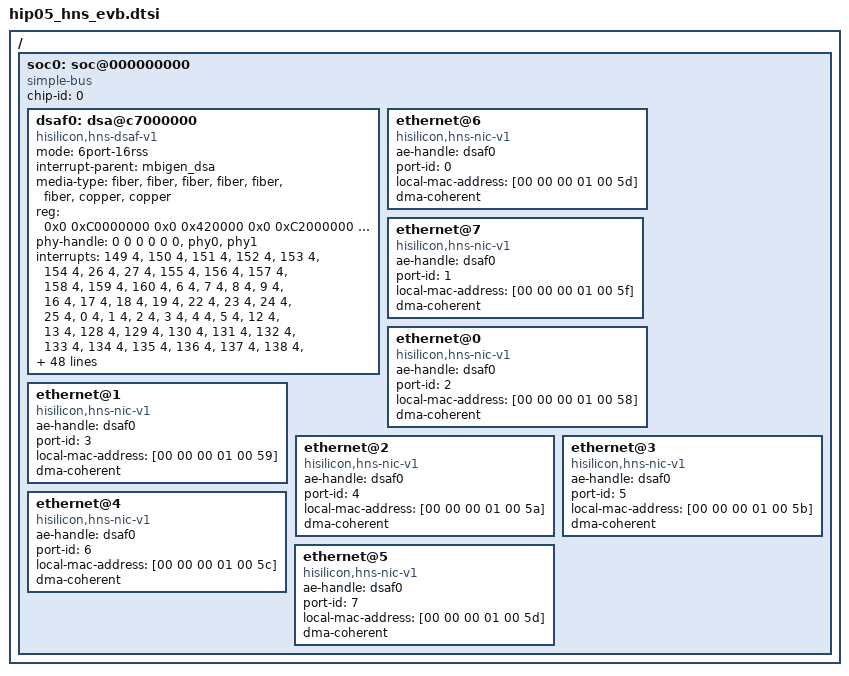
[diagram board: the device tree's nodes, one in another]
/ {
	soc0: soc@000000000 {
		#address-cells = <2>;
		#size-cells = <2>;
		device_type = "soc";
		compatible = "simple-bus";
		ranges = <0x0 0x0 0x0 0x0 0x1 0x0>;
		chip-id = <0>;

		dsaf0: dsa@c7000000 {
			compatible = "hisilicon,hns-dsaf-v1";
			mode = "6port-16rss";
			interrupt-parent = <&mbigen_dsa>;
			media-type = "fiber", "fiber", "fiber", "fiber",
				"fiber", "fiber", "copper", "copper";
			reg = <0x0 0xC0000000 0x0 0x420000
				0x0 0xC2000000 0x0 0x300000
				0x0 0xc5000000 0x0 0x890000
				0x0 0xc7000000 0x0 0x60000
				>;

			phy-handle = <0 0 0 0 0 0 &phy0 &phy1>;
			interrupts =
					/* [14] ge fifo err 8 / xge 6**/
					<149 4>,<150 4>,
					<151 4>,<152 4>,
					<153 4>,<154 4>,
					<26 4>,<27 4>,
					<155 4>,<156 4>,
					<157 4>,<158 4>,
					<159 4>,<160 4>,
					/* [12] rcb com 4*3**/
					<6 4>,<7 4>,
					<8 4>,<9 4>,
					<16 4>,<17 4>,
					<18 4>,<19 4>,
					<22 4>,<23 4>,
					<24 4>,<25 4>,
					/* [8] ppe tnl 0-7***/
					<0 4>,<1 4>,
					<2 4>,<3 4>,
					<4 4>,<5 4>,
					<12 4>,<13 4>,
					/* [21] dsaf event int 3+18**/
					<128 4>,<129 4>,
					<130 4>,<131 4>,
					<132 4>,<133 4>,
					<134 4>,<135 4>,
					<136 4>,<137 4>,
					<138 4>,<139 4>,
					<140 4>,<141 4>,
					<142 4>,<143 4>,
					<144 4>,<145 4>,
					<146 4>,<147 4>,
					<148 4>,
					/* [4] debug rcb 2*2*/
					<14 1>,<15 1>,
					<20 1>,<21 1>,
					/* [256] sevice rcb 2*128*/
					<384 1>,<385 1>,
					<386 1>,<387 1>,
					<388 1>,<389 1>,
					<390 1>,<391 1>,
					<392 1>,<393 1>,
					<394 1>,<395 1>,
					<396 1>,<397 1>,
					<398 1>,<399 1>,
					<400 1>,<401 1>,
					<402 1>,<403 1>,
					<404 1>,<405 1>,
					<406 1>,<407 1>,
					<408 1>,<409 1>,
					<410 1>,<411 1>,
					<412 1>,<413 1>,
					<414 1>,<415 1>,
					<416 1>,<417 1>,
					<418 1>,<419 1>,
					<420 1>,<421 1>,
					<422 1>,<423 1>,
					<424 1>,<425 1>,
					<426 1>,<427 1>,
					<428 1>,<429 1>,
					<430 1>,<431 1>,
					<432 1>,<433 1>,
					<434 1>,<435 1>,
					<436 1>,<437 1>,
					<438 1>,<439 1>,
					<440 1>,<441 1>,
					<442 1>,<443 1>,
					<444 1>,<445 1>,
					<446 1>,<447 1>,
					<448 1>,<449 1>,
					<450 1>,<451 1>,
					<452 1>,<453 1>,
					<454 1>,<455 1>,
					<456 1>,<457 1>,
					<458 1>,<459 1>,
					<460 1>,<461 1>,
					<462 1>,<463 1>,
					<464 1>,<465 1>,
					<466 1>,<467 1>,
					<468 1>,<469 1>,
					<470 1>,<471 1>,
					<472 1>,<473 1>,
					<474 1>,<475 1>,
					<476 1>,<477 1>,
					<478 1>,<479 1>,
					<480 1>,<481 1>,
					<482 1>,<483 1>,
					<484 1>,<485 1>,
					<486 1>,<487 1>,
					<488 1>,<489 1>,
					<490 1>,<491 1>,
					<492 1>,<493 1>,
					<494 1>,<495 1>,
					<496 1>,<497 1>,
					<498 1>,<499 1>,
					<500 1>,<501 1>,
					<502 1>,<503 1>,
					<504 1>,<505 1>,
					<506 1>,<507 1>,
					<508 1>,<509 1>,
					<510 1>,<511 1>,
					<512 1>,<513 1>,
					<514 1>,<515 1>,
					<516 1>,<517 1>,
					<518 1>,<519 1>,
					<520 1>,<521 1>,
					<522 1>,<523 1>,
					<524 1>,<525 1>,
					<526 1>,<527 1>,
					<528 1>,<529 1>,
					<530 1>,<531 1>,
					<532 1>,<533 1>,
					<534 1>,<535 1>,
					<536 1>,<537 1>,
					<538 1>,<539 1>,
					<540 1>,<541 1>,
					<542 1>,<543 1>,
					<544 1>,<545 1>,
					<546 1>,<547 1>,
					<548 1>,<549 1>,
					<550 1>,<551 1>,
					<552 1>,<553 1>,
					<554 1>,<555 1>,
					<556 1>,<557 1>,
					<558 1>,<559 1>,
					<560 1>,<561 1>,
					<562 1>,<563 1>,
					<564 1>,<565 1>,
					<566 1>,<567 1>,
					<568 1>,<569 1>,
					<570 1>,<571 1>,
					<572 1>,<573 1>,
					<574 1>,<575 1>,
					<576 1>,<577 1>,
					<578 1>,<579 1>,
					<580 1>,<581 1>,
					<582 1>,<583 1>,
					<584 1>,<585 1>,
					<586 1>,<587 1>,
					<588 1>,<589 1>,
					<590 1>,<591 1>,
					<592 1>,<593 1>,
					<594 1>,<595 1>,
					<596 1>,<597 1>,
					<598 1>,<599 1>,
					<600 1>,<601 1>,
					<602 1>,<603 1>,
					<604 1>,<605 1>,
					<606 1>,<607 1>,
					<608 1>,<609 1>,
					<610 1>,<611 1>,
					<612 1>,<613 1>,
					<614 1>,<615 1>,
					<616 1>,<617 1>,
					<618 1>,<619 1>,
					<620 1>,<621 1>,
					<622 1>,<623 1>,
					<624 1>,<625 1>,
					<626 1>,<627 1>,
					<628 1>,<629 1>,
					<630 1>,<631 1>,
					<632 1>,<633 1>,
					<634 1>,<635 1>,
					<636 1>,<637 1>,
					<638 1>,<639 1>;

			buf-size = <4096>;
			desc-num = <1024>;
			dma-coherent;
		};

		ethernet@6{
			compatible = "hisilicon,hns-nic-v1";
			ae-handle = <&dsaf0>;
			port-id = <0>;
			local-mac-address = [00 00 00 01 00 5d];
			dma-coherent;
		};
		ethernet@7{
			compatible = "hisilicon,hns-nic-v1";
			ae-handle = <&dsaf0>;
			port-id = <1>;
			local-mac-address = [00 00 00 01 00 5f];
			dma-coherent;
		};
		ethernet@0{
			compatible = "hisilicon,hns-nic-v1";
			ae-handle = <&dsaf0>;
			port-id = <2>;
			local-mac-address = [00 00 00 01 00 58];
			dma-coherent;
		};
		ethernet@1{
			compatible = "hisilicon,hns-nic-v1";
			ae-handle = <&dsaf0>;
			port-id = <3>;
			local-mac-address = [00 00 00 01 00 59];
			dma-coherent;
		};
		ethernet@2{
			compatible = "hisilicon,hns-nic-v1";
			ae-handle = <&dsaf0>;
			port-id = <4>;
			local-mac-address = [00 00 00 01 00 5a];
			dma-coherent;
		};
		ethernet@3{
			compatible = "hisilicon,hns-nic-v1";
			ae-handle = <&dsaf0>;
			port-id = <5>;
			local-mac-address = [00 00 00 01 00 5b];
			dma-coherent;
		};
		ethernet@4{
			compatible = "hisilicon,hns-nic-v1";
			ae-handle = <&dsaf0>;
			port-id = <6>;
			local-mac-address = [00 00 00 01 00 5c];
			dma-coherent;
		};
		ethernet@5{
			compatible = "hisilicon,hns-nic-v1";
			ae-handle = <&dsaf0>;
			port-id = <7>;
			local-mac-address = [00 00 00 01 00 5d];
			dma-coherent;
		};
	};
};
